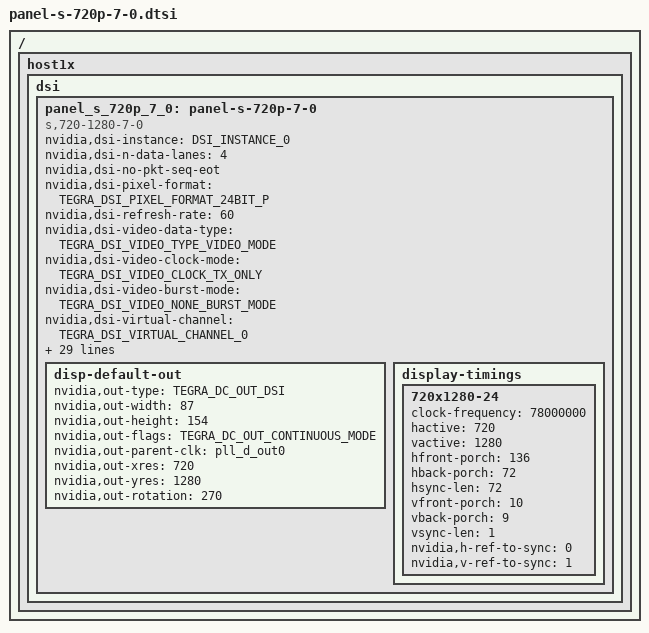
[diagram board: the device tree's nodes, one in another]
/*
 * Samsung AMS699VC01
 *
 * Copyright (c) 2022, CTCaer <ctcaer@gmail.com>
 *
 * This program is free software; you can redistribute it and/or modify
 * it under the terms of the GNU General Public License as published by
 * the Free Software Foundation; version 2 of the License.
 *
 * This program is distributed in the hope that it will be useful, but WITHOUT
 * ANY WARRANTY; without even the implied warranty of MERCHANTABILITY or
 * FITNESS FOR A PARTICULAR PURPOSE.  See the GNU General Public License for
 * more details.
 *
 */
#include <dt-bindings/display/tegra-dc.h>
#include <dt-bindings/display/tegra-panel.h>

/ {
	host1x {
		dsi {
			panel_s_720p_7_0: panel-s-720p-7-0 {
				status = "okay";
				compatible = "s,720-1280-7-0"; /* Compatible id must not change! */
				/*
				nvidia,edid = [
						00 FF FF FF FF FF FF 00 28 89 10 0F 00 00 00 00
						01 1A 01 03 80 08 0E 00 1A 00 00 00 00 00 00 00
						00 00 00 00 00 00 01 01 01 01 01 01 01 01 01 01
						01 01 01 01 01 01 78 1E D0 18 21 00 14 50 88 48
						A1 00 4D 89 00 00 00 00 00 00 00 10 00 00 00 00
						00 00 00 00 00 00 00 00 00 00 00 00 00 10 00 00
						00 00 00 00 00 00 00 00 00 00 00 00 00 00 00 10
						00 00 00 00 00 00 00 00 00 00 00 00 00 00 00 DD];
				*/
				nvidia,dsi-instance = <DSI_INSTANCE_0>;
				nvidia,dsi-n-data-lanes = <4>;
				/*nvidia,dsi-lp-cmd-mode-freq = <100000>; not parsed and so 10MHz is used */
				/*nvidia,dsi-lp-read-cmd-mode-freq = <100000>; not parsed and so 10MHz is used */
				nvidia,dsi-no-pkt-seq-eot; /* Not parsed and not needed because no burst */
				nvidia,dsi-pixel-format = <TEGRA_DSI_PIXEL_FORMAT_24BIT_P>;
				nvidia,dsi-refresh-rate = <60>;
				nvidia,dsi-video-data-type = <TEGRA_DSI_VIDEO_TYPE_VIDEO_MODE>;
				nvidia,dsi-video-clock-mode = <TEGRA_DSI_VIDEO_CLOCK_TX_ONLY>;
				nvidia,dsi-video-burst-mode = <TEGRA_DSI_VIDEO_NONE_BURST_MODE>;
				nvidia,dsi-virtual-channel = <TEGRA_DSI_VIRTUAL_CHANNEL_0>;
				nvidia,dsi-panel-reset = <TEGRA_DSI_ENABLE>;
				nvidia,dsi-power-saving-suspend = <TEGRA_DSI_ENABLE>;
				nvidia,dsi-ulpm-not-support = <TEGRA_DSI_ENABLE>;
				/*nvidia,dsi-suspend-aggr = <DSI_HOST_SUSPEND_LV2>;*/
				nvidia,dsi-phy-tlpx = <100>;
				nvidia,dsi-phy-wakeup = <1970>;
				nvidia,dsi-phy-taget = <450>;
				nvidia,dsi-phy-tasure = <180>;
				nvidia,dsi-phy-tago = <360>;
				nvidia,dsi-init-cmd =
					<TEGRA_DSI_PACKET_CMD DSI_DCS_WRITE_0_PARAM DSI_DCS_EXIT_SLEEP_MODE 0x00 0x0>,
					<TEGRA_DSI_DELAY_MS 180>, //180ms
					<TEGRA_DSI_PACKET_CMD DSI_DCS_WRITE_0_PARAM 0xA0 0x23 0x0>,
					<TEGRA_DSI_PACKET_CMD DSI_DCS_WRITE_0_PARAM 0x53 0x28 0x0>,
					<TEGRA_DSI_PACKET_CMD DSI_DCS_LONG_WRITE 0x05 0x00 0x0
						0xE2 0x5A 0x5A 0x5A 0x5A
						0x0 0x0>,
					<TEGRA_DSI_PACKET_CMD DSI_DCS_WRITE_0_PARAM 0xB0 0x07 0x0>,
					<TEGRA_DSI_PACKET_CMD DSI_DCS_WRITE_0_PARAM 0xB1 0x06 0x0>,
					<TEGRA_DSI_PACKET_CMD DSI_DCS_LONG_WRITE 0x05 0x00 0x0
						0xE2 0x5A 0x5A 0xA5 0xA5
						0x0 0x0>,
					<TEGRA_DSI_PACKET_CMD DSI_DCS_LONG_WRITE 0x03 0x00 0x0
						0x51 0x00 0x00
						0x0 0x0>,
					<TEGRA_DSI_DELAY_MS 5>, //5ms
					/* TODO, Do we need to find a way to set set_display_on after "operate DSI_A in video mode"? */
					<TEGRA_DSI_PACKET_CMD DSI_DCS_WRITE_0_PARAM DSI_DCS_SET_DISPLAY_ON 0x00 0x0>,
					<TEGRA_DSI_DELAY_MS 20>; //20ms
				nvidia,dsi-n-init-cmd = <12>;
				nvidia,dsi-suspend-cmd =
					<TEGRA_DSI_PACKET_CMD DSI_DCS_WRITE_0_PARAM DSI_DCS_SET_DISPLAY_OFF 0x00 0x0>,
					<TEGRA_DSI_DELAY_MS 40>, //40ms + 10ms
					<TEGRA_DSI_PACKET_CMD DSI_DCS_WRITE_0_PARAM DSI_DCS_ENTER_SLEEP_MODE 0x00 0x0>,
					<TEGRA_DSI_DELAY_MS 120>; //120ms
				nvidia,dsi-n-suspend-cmd = <4>;
				disp-default-out {
					nvidia,out-type = <TEGRA_DC_OUT_DSI>;
					nvidia,out-width = <87>;
					nvidia,out-height = <154>;
					nvidia,out-flags = <TEGRA_DC_OUT_CONTINUOUS_MODE>;
					nvidia,out-parent-clk = "pll_d_out0";
					nvidia,out-xres = <720>;
					nvidia,out-yres = <1280>;
					nvidia,out-rotation = <270>;
				};
				display-timings {
					720x1280-24 {
						clock-frequency = <78000000>; /* (720+136+144) x (1280+10+10) x 60 */
						hactive = <720>;
						vactive = <1280>;

						hfront-porch = <136>;
						hback-porch = <72>;
						hsync-len = <72>;

						vfront-porch = <10>;
						vback-porch = <9>;
						vsync-len = <1>;

						/* For DSI these are automatically calculated */
						nvidia,h-ref-to-sync = <0>;
						nvidia,v-ref-to-sync = <1>;
					};
				};
			};
		};
	};
};
